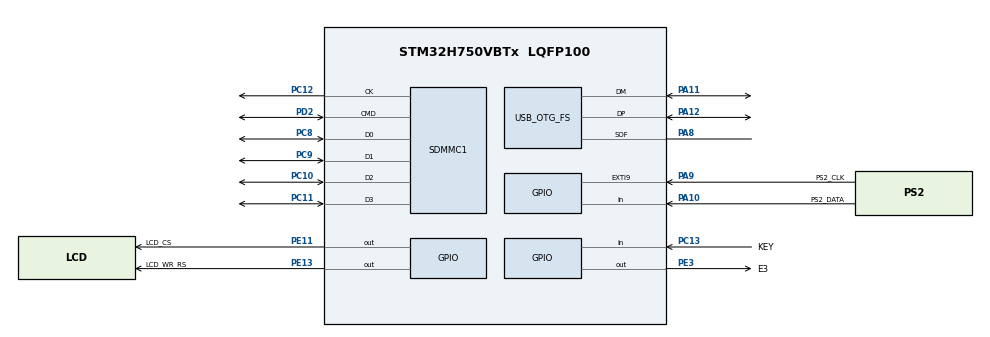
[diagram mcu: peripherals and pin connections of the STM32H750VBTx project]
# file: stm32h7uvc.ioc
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CORTEX_M7.CPU_DCache=Disabled
CORTEX_M7.CPU_ICache=Enabled
FATFS._FS_EXFAT=1
FATFS._LFN_UNICODE=1
FATFS._USE_LFN=1
FATFS._USE_MKFS=0
JPEG.USE_JPEG_DECODER=0
JPEG.USE_JPEG_ENCODER=1
Mcu.Family=STM32H7
Mcu.Name=STM32H750VBTx
Mcu.Package=LQFP100
Mdma.MDMA_Channel0.JPEG_INFIFO_TH.0.BlockCount=0
Mdma.MDMA_Channel0.JPEG_INFIFO_TH.0.BlockDataLength=0
Mdma.MDMA_Channel0.JPEG_INFIFO_TH.0.BufferTransferLength=32
Mdma.MDMA_Channel0.JPEG_INFIFO_TH.0.CircularMode=MDMA_LINEAR_LIST
Mdma.MDMA_Channel0.JPEG_INFIFO_TH.0.DataAlignment=MDMA_DATAALIGN_PACKENABLE
Mdma.MDMA_Channel0.JPEG_INFIFO_TH.0.DestBlockAddressOffset=0
Mdma.MDMA_Channel0.JPEG_INFIFO_TH.0.DestBurst=MDMA_DEST_BURST_16BEATS
Mdma.MDMA_Channel0.JPEG_INFIFO_TH.0.DestDataSize=MDMA_DEST_DATASIZE_WORD
Mdma.MDMA_Channel0.JPEG_INFIFO_TH.0.DestinationInc=MDMA_DEST_INC_DISABLE
Mdma.MDMA_Channel0.JPEG_INFIFO_TH.0.DstAddress=0
Mdma.MDMA_Channel0.JPEG_INFIFO_TH.0.Endianness=MDMA_LITTLE_ENDIANNESS_PRESERVE
Mdma.MDMA_Channel0.JPEG_INFIFO_TH.0.Instance=MDMA_Channel0
Mdma.MDMA_Channel0.JPEG_INFIFO_TH.0.MaskAddress=0
Mdma.MDMA_Channel0.JPEG_INFIFO_TH.0.MaskData=0
Mdma.MDMA_Channel0.JPEG_INFIFO_TH.0.Priority=MDMA_PRIORITY_HIGH
Mdma.MDMA_Channel0.JPEG_INFIFO_TH.0.Rank=First
Mdma.MDMA_Channel0.JPEG_INFIFO_TH.0.SourceBlockAddressOffset=0
Mdma.MDMA_Channel0.JPEG_INFIFO_TH.0.SourceBurst=MDMA_SOURCE_BURST_32BEATS
Mdma.MDMA_Channel0.JPEG_INFIFO_TH.0.SourceDataSize=MDMA_SRC_DATASIZE_BYTE
Mdma.MDMA_Channel0.JPEG_INFIFO_TH.0.SourceInc=MDMA_SRC_INC_BYTE
Mdma.MDMA_Channel0.JPEG_INFIFO_TH.0.SrcAddress=0
Mdma.MDMA_Channel0.JPEG_INFIFO_TH.0.TransferTriggerMode=MDMA_BUFFER_TRANSFER
Mdma.MDMA_Channel0.Request0=JPEG_INFIFO_TH
Mdma.MDMA_Channel0.RequestsNb=1
Mdma.MDMA_Channel1.JPEG_OUTFIFO_TH.0.BlockCount=0
Mdma.MDMA_Channel1.JPEG_OUTFIFO_TH.0.BlockDataLength=0
Mdma.MDMA_Channel1.JPEG_OUTFIFO_TH.0.BufferTransferLength=32
Mdma.MDMA_Channel1.JPEG_OUTFIFO_TH.0.CircularMode=MDMA_LINEAR_LIST
Mdma.MDMA_Channel1.JPEG_OUTFIFO_TH.0.DataAlignment=MDMA_DATAALIGN_PACKENABLE
Mdma.MDMA_Channel1.JPEG_OUTFIFO_TH.0.DestBlockAddressOffset=0
Mdma.MDMA_Channel1.JPEG_OUTFIFO_TH.0.DestBurst=MDMA_DEST_BURST_32BEATS
Mdma.MDMA_Channel1.JPEG_OUTFIFO_TH.0.DestDataSize=MDMA_DEST_DATASIZE_BYTE
Mdma.MDMA_Channel1.JPEG_OUTFIFO_TH.0.DestinationInc=MDMA_DEST_INC_BYTE
Mdma.MDMA_Channel1.JPEG_OUTFIFO_TH.0.DstAddress=0
Mdma.MDMA_Channel1.JPEG_OUTFIFO_TH.0.Endianness=MDMA_LITTLE_ENDIANNESS_PRESERVE
Mdma.MDMA_Channel1.JPEG_OUTFIFO_TH.0.Instance=MDMA_Channel1
Mdma.MDMA_Channel1.JPEG_OUTFIFO_TH.0.MaskAddress=0
Mdma.MDMA_Channel1.JPEG_OUTFIFO_TH.0.MaskData=0
Mdma.MDMA_Channel1.JPEG_OUTFIFO_TH.0.Priority=MDMA_PRIORITY_VERY_HIGH
Mdma.MDMA_Channel1.JPEG_OUTFIFO_TH.0.Rank=First
Mdma.MDMA_Channel1.JPEG_OUTFIFO_TH.0.SourceBlockAddressOffset=0
Mdma.MDMA_Channel1.JPEG_OUTFIFO_TH.0.SourceBurst=MDMA_SOURCE_BURST_32BEATS
Mdma.MDMA_Channel1.JPEG_OUTFIFO_TH.0.SourceDataSize=MDMA_SRC_DATASIZE_WORD
Mdma.MDMA_Channel1.JPEG_OUTFIFO_TH.0.SourceInc=MDMA_SRC_INC_DISABLE
Mdma.MDMA_Channel1.JPEG_OUTFIFO_TH.0.SrcAddress=0
Mdma.MDMA_Channel1.JPEG_OUTFIFO_TH.0.TransferTriggerMode=MDMA_BUFFER_TRANSFER
Mdma.MDMA_Channel1.Request0=JPEG_OUTFIFO_TH
Mdma.MDMA_Channel1.RequestsNb=1
Mdma.RequestSet0=MDMA_Channel0
Mdma.RequestSet1=MDMA_Channel1
Mdma.RequestSetsNb=2
NVIC.EXTI9_5_IRQn=true\:0\:0\:false\:false\:true\:true\:true\:true
NVIC.JPEG_IRQn=true\:0\:0\:false\:false\:true\:true\:true\:true
NVIC.MDMA_IRQn=true\:0\:0\:false\:false\:true\:false\:true\:true
NVIC.OTG_FS_IRQn=true\:0\:0\:false\:false\:true\:false\:true\:true
NVIC.PriorityGroup=NVIC_PRIORITYGROUP_4
PA10.GPIO_Label=PS2_DATA
PA10.GPIO_PuPd=GPIO_PULLDOWN
PA10.Signal=GPIO_Input
PA11.Mode=Device_Only
PA11.Signal=USB_OTG_FS_DM
PA12.Mode=Device_Only
PA12.Signal=USB_OTG_FS_DP
PA13\ (JTMS/SWDIO).Mode=Serial_Wire
PA13\ (JTMS/SWDIO).Signal=DEBUG_JTMS-SWDIO
PA14\ (JTCK/SWCLK).Mode=Serial_Wire
PA14\ (JTCK/SWCLK).Signal=DEBUG_JTCK-SWCLK
PA8.Mode=Activate_SOF_FS
PA8.Signal=USB_OTG_FS_SOF
PA9.GPIO_Label=PS2_CLK
PA9.GPIO_ModeDefaultEXTI=GPIO_MODE_IT_FALLING
PA9.GPIO_PuPd=GPIO_PULLDOWN
PA9.Signal=GPXTI9
PC10.Mode=SD_4_bits_Wide_bus
PC10.Signal=SDMMC1_D2
PC11.Mode=SD_4_bits_Wide_bus
PC11.Signal=SDMMC1_D3
PC12.Mode=SD_4_bits_Wide_bus
PC12.Signal=SDMMC1_CK
PC13.GPIO_Label=KEY
PC13.GPIO_PuPd=GPIO_PULLDOWN
PC13.Signal=GPIO_Input
PC14-OSC32_IN\ (OSC32_IN).Mode=LSE-External-Oscillator
PC14-OSC32_IN\ (OSC32_IN).Signal=RCC_OSC32_IN
PC15-OSC32_OUT\ (OSC32_OUT).Mode=LSE-External-Oscillator
PC15-OSC32_OUT\ (OSC32_OUT).Signal=RCC_OSC32_OUT
PC8.Mode=SD_4_bits_Wide_bus
PC8.Signal=SDMMC1_D0
PC9.Mode=SD_4_bits_Wide_bus
PC9.Signal=SDMMC1_D1
PD2.Mode=SD_4_bits_Wide_bus
PD2.Signal=SDMMC1_CMD
PE10.Signal=TIM1_CH2N
PE11.GPIO_Label=LCD_CS
PE11.GPIO_Speed=GPIO_SPEED_FREQ_VERY_HIGH
PE11.PinState=GPIO_PIN_SET
PE11.Signal=GPIO_Output
PE12.GPIO_Speed=GPIO_SPEED_FREQ_HIGH
PE12.Signal=SPI4_SCK
PE13.GPIO_Label=LCD_WR_RS
PE13.GPIO_Speed=GPIO_SPEED_FREQ_VERY_HIGH
PE13.PinState=GPIO_PIN_SET
PE13.Signal=GPIO_Output
PE14.GPIO_Speed=GPIO_SPEED_FREQ_HIGH
PE14.Signal=SPI4_MOSI
PE3.GPIO_Label=E3
PE3.PinState=GPIO_PIN_RESET
PE3.Signal=GPIO_Output
PH0-OSC_IN\ (PH0).Mode=HSE-External-Oscillator
PH0-OSC_IN\ (PH0).Signal=RCC_OSC_IN
PH1-OSC_OUT\ (PH1).Mode=HSE-External-Oscillator
PH1-OSC_OUT\ (PH1).Signal=RCC_OSC_OUT
ProjectManager.HeapSize=0x200
ProjectManager.StackSize=0x400
ProjectManager.TargetToolchain=STM32CubeIDE
RCC.ADCFreq_Value=75000000
RCC.APB1Freq_Value=120000000
RCC.APB2Freq_Value=120000000
RCC.APB3Freq_Value=120000000
RCC.APB4Freq_Value=120000000
RCC.CortexFreq_Value=480000000
RCC.D1PPRE=RCC_APB3_DIV2
RCC.D2PPRE1=RCC_APB1_DIV2
RCC.D2PPRE2=RCC_APB2_DIV2
RCC.D3PPRE=RCC_APB4_DIV2
RCC.DIVM1=5
RCC.DIVM2=2
RCC.DIVM3=5
RCC.DIVN1=192
RCC.DIVN2=12
RCC.DIVN3=50
RCC.DIVQ2=1
RCC.DIVR2=1
RCC.HCLKFreq_Value=240000000
RCC.HPRE=RCC_HCLK_DIV2
RCC.HSE_VALUE=25000000
RCC.PLLFRACN=0
RCC.PLLSourceVirtual=RCC_PLLSOURCE_HSE
RCC.PWR_Regulator_Voltage_Scale=PWR_REGULATOR_VOLTAGE_SCALE0
RCC.RTCClockSelection=RCC_RTCCLKSOURCE_LSE
RCC.SDMMC1CLockSelection=RCC_SDMMCCLKSOURCE_PLL2
RCC.SPI123CLockSelection=RCC_SPI123CLKSOURCE_PLL2
RCC.SYSCLKFreq_VALUE=480000000
RCC.SYSCLKSource=RCC_SYSCLKSOURCE_PLLCLK
RCC.Spi45ClockSelection=RCC_SPI45CLKSOURCE_PLL3
RCC.USBCLockSelection=RCC_USBCLKSOURCE_HSI48
RCC.USBFreq_Value=48000000
RTC.Hours=12
RTC.Month=RTC_MONTH_JUNE
RTC.Year=20
SDMMC1.ClockDiv=5
USB_DEVICE.CLASS_NAME_FS=CDC
USB_DEVICE.CONFIGURATION_STRING_CDC_FS=Video Config
USB_DEVICE.INTERFACE_STRING_CDC_FS=Video Interface
USB_DEVICE.PID_CDC_FS=0x1706
USB_DEVICE.PRODUCT_STRING_CDC_FS=STM32 Video Demo
USB_DEVICE.VID-CDC_FS=0xC251
USB_DEVICE.VirtualMode-CDC_FS=Cdc
USB_DEVICE.VirtualModeFS=Cdc_FS
USB_OTG_FS.VirtualMode=Device_Only
USB_OTG_FS.dma_enable=DISABLE
VP_FATFS_VS_SDIO.Mode=SDIO
VP_JPEG_VS_JPEG.Mode=JPEG_Activate
VP_MEMORYMAP_VS_MEMORYMAP.Mode=CurAppReg
VP_RTC_VS_RTC_Activate.Mode=RTC_Enabled
VP_RTC_VS_RTC_Calendar.Mode=RTC_Calendar
VP_USB_DEVICE_VS_USB_DEVICE_CDC_FS.Mode=CDC_FS
board=custom

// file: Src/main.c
/* USER CODE BEGIN Header */
/**
  ******************************************************************************
  * @file           : main.c
  * @brief          : Main program body
  ******************************************************************************
  * @attention
  *
  * Copyright (c) 2024 STMicroelectronics.
  * All rights reserved.
  *
  * This software is licensed under terms that can be found in the LICENSE file
  * in the root directory of this software component.
  * If no LICENSE file comes with this software, it is provided AS-IS.
  *
  ******************************************************************************
  */
/* USER CODE END Header */
#include "main.h"
#include "fatfs.h"
#include "jpeg.h"
#include "mdma.h"
#include "memorymap.h"
#include "quadspi.h"
#include "rtc.h"
#include "sdmmc.h"
#include "gpio.h"

/* USER CODE BEGIN Includes */
#include "usbd_core.h"
#include "usbd_desc.h"
#include "usbd_video_if.h"
#include "startup.h"
/* USER CODE END Includes */

void SystemClock_Config(void);
void PeriphCommonClock_Config(void);

int main(void)
{

  /* Enable the CPU Cache */

  /* Enable I-Cache---------------------------------------------------------*/
  SCB_EnableICache();

  /* MCU Configuration--------------------------------------------------------*/

  /* Reset of all peripherals, Initializes the Flash interface and the Systick. */
  HAL_Init();

  /* Configure the system clock */
  SystemClock_Config();

  /* Configure the peripherals common clocks */
  PeriphCommonClock_Config();

  /* USER CODE BEGIN SysInit */
  initialize();
  /* USER CODE END SysInit */

  /* Initialize all configured peripherals */
  MX_GPIO_Init();
  MX_MDMA_Init();
  MX_RTC_Init();
  MX_SDMMC1_SD_Init();
  MX_FATFS_Init();
  MX_JPEG_Init();
  MX_QUADSPI_Init();
  /* USER CODE BEGIN 2 */
  setup();
  /* USER CODE END 2 */

  /* Infinite loop */
  while (1)
  {

    /* USER CODE BEGIN 3 */
	loop();
  }
  /* USER CODE END 3 */
}

void SystemClock_Config(void)
{
  RCC_OscInitTypeDef RCC_OscInitStruct = {0};
  RCC_ClkInitTypeDef RCC_ClkInitStruct = {0};

  /** Supply configuration update enable
  */
  HAL_PWREx_ConfigSupply(PWR_LDO_SUPPLY);

  /** Configure the main internal regulator output voltage
  */
  __HAL_PWR_VOLTAGESCALING_CONFIG(PWR_REGULATOR_VOLTAGE_SCALE0);

  while(!__HAL_PWR_GET_FLAG(PWR_FLAG_VOSRDY)) {}

  /** Configure LSE Drive Capability
  */
  HAL_PWR_EnableBkUpAccess();
  __HAL_RCC_LSEDRIVE_CONFIG(RCC_LSEDRIVE_LOW);

  /** Initializes the RCC Oscillators according to the specified parameters
  * in the RCC_OscInitTypeDef structure.
  */
  RCC_OscInitStruct.OscillatorType = RCC_OSCILLATORTYPE_HSI48|RCC_OSCILLATORTYPE_HSE
                              |RCC_OSCILLATORTYPE_LSE;
  RCC_OscInitStruct.HSEState = RCC_HSE_ON;
  RCC_OscInitStruct.LSEState = RCC_LSE_ON;
  RCC_OscInitStruct.HSI48State = RCC_HSI48_ON;
  RCC_OscInitStruct.PLL.PLLState = RCC_PLL_ON;
  RCC_OscInitStruct.PLL.PLLSource = RCC_PLLSOURCE_HSE;
  RCC_OscInitStruct.PLL.PLLM = 5;
  RCC_OscInitStruct.PLL.PLLN = 192;
  RCC_OscInitStruct.PLL.PLLP = 2;
  RCC_OscInitStruct.PLL.PLLQ = 8;
  RCC_OscInitStruct.PLL.PLLR = 2;
  RCC_OscInitStruct.PLL.PLLRGE = RCC_PLL1VCIRANGE_2;
  RCC_OscInitStruct.PLL.PLLVCOSEL = RCC_PLL1VCOWIDE;
  RCC_OscInitStruct.PLL.PLLFRACN = 0;
  if (HAL_RCC_OscConfig(&RCC_OscInitStruct) != HAL_OK)
  {
    Error_Handler();
  }

  /** Initializes the CPU, AHB and APB buses clocks
  */
  RCC_ClkInitStruct.ClockType = RCC_CLOCKTYPE_HCLK|RCC_CLOCKTYPE_SYSCLK
                              |RCC_CLOCKTYPE_PCLK1|RCC_CLOCKTYPE_PCLK2
                              |RCC_CLOCKTYPE_D3PCLK1|RCC_CLOCKTYPE_D1PCLK1;
  RCC_ClkInitStruct.SYSCLKSource = RCC_SYSCLKSOURCE_PLLCLK;
  RCC_ClkInitStruct.SYSCLKDivider = RCC_SYSCLK_DIV1;
  RCC_ClkInitStruct.AHBCLKDivider = RCC_HCLK_DIV2;
  RCC_ClkInitStruct.APB3CLKDivider = RCC_APB3_DIV2;
  RCC_ClkInitStruct.APB1CLKDivider = RCC_APB1_DIV2;
  RCC_ClkInitStruct.APB2CLKDivider = RCC_APB2_DIV2;
  RCC_ClkInitStruct.APB4CLKDivider = RCC_APB4_DIV2;

  if (HAL_RCC_ClockConfig(&RCC_ClkInitStruct, FLASH_LATENCY_4) != HAL_OK)
  {
    Error_Handler();
  }
}

void PeriphCommonClock_Config(void)
{
  RCC_PeriphCLKInitTypeDef PeriphClkInitStruct = {0};

  /** Initializes the peripherals clock
  */
  PeriphClkInitStruct.PeriphClockSelection = RCC_PERIPHCLK_QSPI|RCC_PERIPHCLK_SDMMC;
  PeriphClkInitStruct.PLL2.PLL2M = 5;
  PeriphClkInitStruct.PLL2.PLL2N = 133;
  PeriphClkInitStruct.PLL2.PLL2P = 5;
  PeriphClkInitStruct.PLL2.PLL2Q = 1;
  PeriphClkInitStruct.PLL2.PLL2R = 5;
  PeriphClkInitStruct.PLL2.PLL2RGE = RCC_PLL2VCIRANGE_2;
  PeriphClkInitStruct.PLL2.PLL2VCOSEL = RCC_PLL2VCOWIDE;
  PeriphClkInitStruct.PLL2.PLL2FRACN = 0;
  PeriphClkInitStruct.QspiClockSelection = RCC_QSPICLKSOURCE_PLL2;
  PeriphClkInitStruct.SdmmcClockSelection = RCC_SDMMCCLKSOURCE_PLL2;
  if (HAL_RCCEx_PeriphCLKConfig(&PeriphClkInitStruct) != HAL_OK)
  {
    Error_Handler();
  }
}

void Error_Handler(void)
{
  __disable_irq();
  while (1)
  {
  }
}
